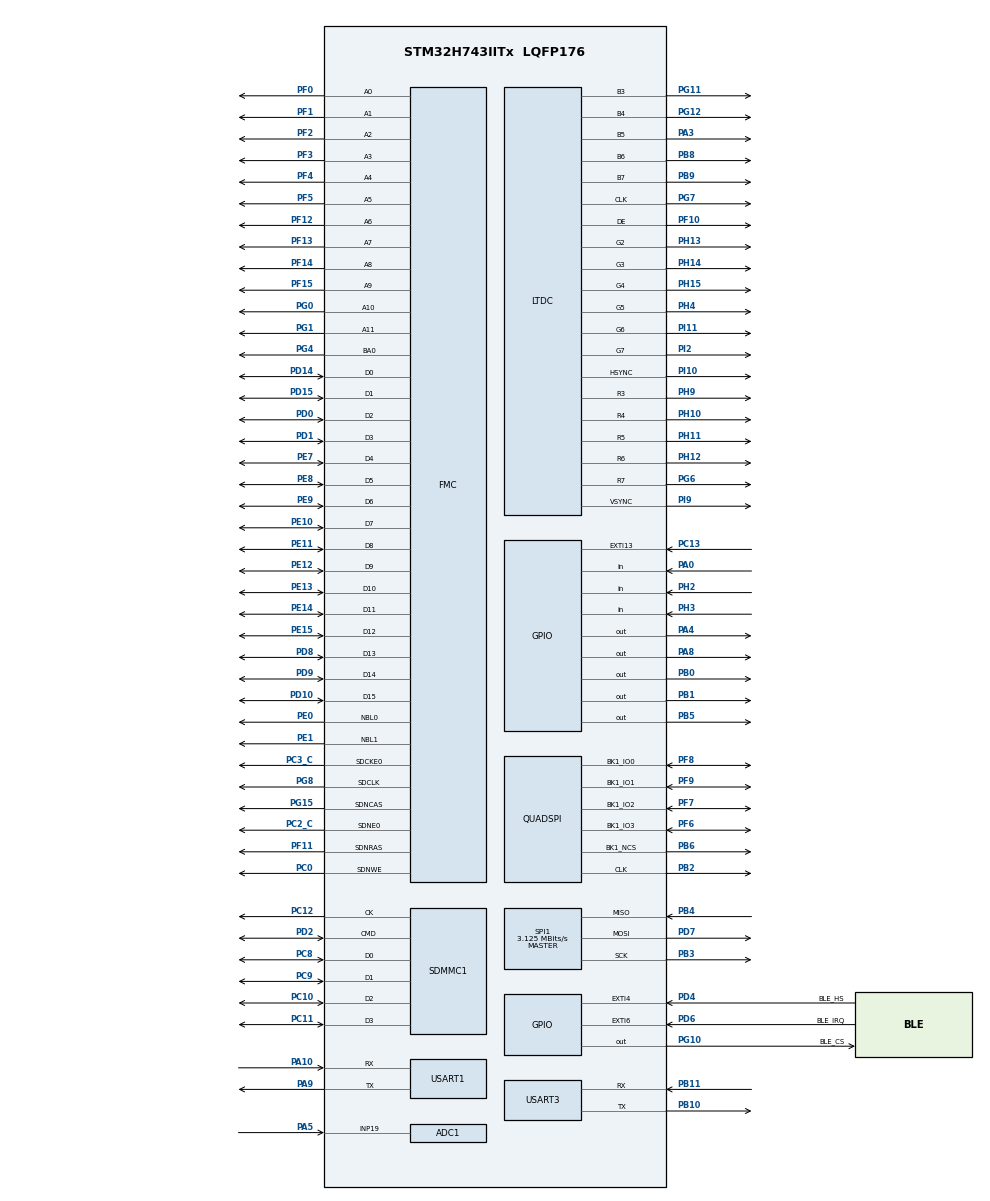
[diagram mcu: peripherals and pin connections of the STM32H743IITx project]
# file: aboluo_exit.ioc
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ADC1.Channel-0\#ChannelRegularConversion=ADC_CHANNEL_19
ADC1.NbrOfConversionFlag=1
ADC1.OffsetNumber-0\#ChannelRegularConversion=ADC_OFFSET_NONE
ADC1.OffsetSignedSaturation-0\#ChannelRegularConversion=DISABLE
ADC1.Rank-0\#ChannelRegularConversion=1
ADC1.SamplingTime-0\#ChannelRegularConversion=ADC_SAMPLETIME_1CYCLE_5
ADC1.master=1
CORTEX_M7.AccessPermission_S-Cortex_Memory_Protection_Unit_Region1_Settings_S=MPU_REGION_FULL_ACCESS
CORTEX_M7.AccessPermission_S-Cortex_Memory_Protection_Unit_Region2_Settings_S=MPU_REGION_FULL_ACCESS
CORTEX_M7.AccessPermission_S-Cortex_Memory_Protection_Unit_Region3_Settings_S=MPU_REGION_FULL_ACCESS
CORTEX_M7.AccessPermission_S-Cortex_Memory_Protection_Unit_Region4_Settings_S=MPU_REGION_FULL_ACCESS
CORTEX_M7.AccessPermission_S-Cortex_Memory_Protection_Unit_Region6_Settings_S=MPU_REGION_FULL_ACCESS
CORTEX_M7.AccessPermission_S-Cortex_Memory_Protection_Unit_Region7_Settings_S=MPU_REGION_FULL_ACCESS
CORTEX_M7.BaseAddress_S-Cortex_Memory_Protection_Unit_Region1_Settings_S=0x20000000
CORTEX_M7.BaseAddress_S-Cortex_Memory_Protection_Unit_Region2_Settings_S=0x24000000
CORTEX_M7.BaseAddress_S-Cortex_Memory_Protection_Unit_Region3_Settings_S=0x30000000
CORTEX_M7.BaseAddress_S-Cortex_Memory_Protection_Unit_Region4_Settings_S=0x38000000
CORTEX_M7.BaseAddress_S-Cortex_Memory_Protection_Unit_Region5_Settings_S=0x60000000
CORTEX_M7.BaseAddress_S-Cortex_Memory_Protection_Unit_Region6_Settings_S=0xC0000000
CORTEX_M7.BaseAddress_S-Cortex_Memory_Protection_Unit_Region7_Settings_S=0x80000000
CORTEX_M7.CPU_DCache=Enabled
CORTEX_M7.CPU_ICache=Enabled
CORTEX_M7.DisableExec_S-Cortex_Memory_Protection_Unit_Region7_Settings_S=MPU_INSTRUCTION_ACCESS_DISABLE
CORTEX_M7.Enable_S-Cortex_Memory_Protection_Unit_Region1_Settings_S=MPU_REGION_ENABLE
CORTEX_M7.Enable_S-Cortex_Memory_Protection_Unit_Region2_Settings_S=MPU_REGION_ENABLE
CORTEX_M7.Enable_S-Cortex_Memory_Protection_Unit_Region3_Settings_S=MPU_REGION_ENABLE
CORTEX_M7.Enable_S-Cortex_Memory_Protection_Unit_Region4_Settings_S=MPU_REGION_ENABLE
CORTEX_M7.Enable_S-Cortex_Memory_Protection_Unit_Region5_Settings_S=MPU_REGION_ENABLE
CORTEX_M7.Enable_S-Cortex_Memory_Protection_Unit_Region6_Settings_S=MPU_REGION_ENABLE
CORTEX_M7.Enable_S-Cortex_Memory_Protection_Unit_Region7_Settings_S=MPU_REGION_ENABLE
CORTEX_M7.IsBufferable_S-Cortex_Memory_Protection_Unit_Region1_Settings_S=MPU_ACCESS_BUFFERABLE
CORTEX_M7.IsBufferable_S-Cortex_Memory_Protection_Unit_Region2_Settings_S=MPU_ACCESS_BUFFERABLE
CORTEX_M7.IsBufferable_S-Cortex_Memory_Protection_Unit_Region3_Settings_S=MPU_ACCESS_BUFFERABLE
CORTEX_M7.IsBufferable_S-Cortex_Memory_Protection_Unit_Region4_Settings_S=MPU_ACCESS_BUFFERABLE
CORTEX_M7.IsBufferable_S-Cortex_Memory_Protection_Unit_Region6_Settings_S=MPU_ACCESS_NOT_BUFFERABLE
CORTEX_M7.IsCacheable_S-Cortex_Memory_Protection_Unit_Region1_Settings_S=MPU_ACCESS_CACHEABLE
CORTEX_M7.IsCacheable_S-Cortex_Memory_Protection_Unit_Region2_Settings_S=MPU_ACCESS_CACHEABLE
CORTEX_M7.IsCacheable_S-Cortex_Memory_Protection_Unit_Region3_Settings_S=MPU_ACCESS_CACHEABLE
CORTEX_M7.IsCacheable_S-Cortex_Memory_Protection_Unit_Region4_Settings_S=MPU_ACCESS_CACHEABLE
CORTEX_M7.IsCacheable_S-Cortex_Memory_Protection_Unit_Region6_Settings_S=MPU_ACCESS_CACHEABLE
CORTEX_M7.Size_S-Cortex_Memory_Protection_Unit_Region1_Settings_S=MPU_REGION_SIZE_128KB
CORTEX_M7.Size_S-Cortex_Memory_Protection_Unit_Region2_Settings_S=MPU_REGION_SIZE_512KB
CORTEX_M7.Size_S-Cortex_Memory_Protection_Unit_Region3_Settings_S=MPU_REGION_SIZE_512KB
CORTEX_M7.Size_S-Cortex_Memory_Protection_Unit_Region4_Settings_S=MPU_REGION_SIZE_64KB
CORTEX_M7.Size_S-Cortex_Memory_Protection_Unit_Region5_Settings_S=MPU_REGION_SIZE_64MB
CORTEX_M7.Size_S-Cortex_Memory_Protection_Unit_Region6_Settings_S=MPU_REGION_SIZE_32MB
CORTEX_M7.Size_S-Cortex_Memory_Protection_Unit_Region7_Settings_S=MPU_REGION_SIZE_256MB
CORTEX_M7.default_mode_Activation=1
DMA2D.ColorMode=DMA2D_OUTPUT_RGB565
Dma.Request0=USART1_RX
Dma.Request1=USART3_RX
Dma.Request2=SPI1_RX
Dma.Request3=SPI1_TX
Dma.SPI1_RX.2.Direction=DMA_PERIPH_TO_MEMORY
Dma.SPI1_RX.2.EventEnable=DISABLE
Dma.SPI1_RX.2.FIFOMode=DMA_FIFOMODE_DISABLE
Dma.SPI1_RX.2.Instance=DMA1_Stream2
Dma.SPI1_RX.2.MemDataAlignment=DMA_MDATAALIGN_BYTE
Dma.SPI1_RX.2.MemInc=DMA_MINC_ENABLE
Dma.SPI1_RX.2.Mode=DMA_NORMAL
Dma.SPI1_RX.2.PeriphDataAlignment=DMA_PDATAALIGN_BYTE
Dma.SPI1_RX.2.PeriphInc=DMA_PINC_DISABLE
Dma.SPI1_RX.2.Polarity=HAL_DMAMUX_REQ_GEN_RISING
Dma.SPI1_RX.2.Priority=DMA_PRIORITY_HIGH
Dma.SPI1_RX.2.RequestNumber=1
Dma.SPI1_RX.2.SignalID=NONE
Dma.SPI1_RX.2.SyncEnable=DISABLE
Dma.SPI1_RX.2.SyncPolarity=HAL_DMAMUX_SYNC_NO_EVENT
Dma.SPI1_RX.2.SyncRequestNumber=1
Dma.SPI1_RX.2.SyncSignalID=NONE
Dma.SPI1_TX.3.Direction=DMA_MEMORY_TO_PERIPH
Dma.SPI1_TX.3.EventEnable=DISABLE
Dma.SPI1_TX.3.FIFOMode=DMA_FIFOMODE_DISABLE
Dma.SPI1_TX.3.Instance=DMA1_Stream3
Dma.SPI1_TX.3.MemDataAlignment=DMA_MDATAALIGN_BYTE
Dma.SPI1_TX.3.MemInc=DMA_MINC_ENABLE
Dma.SPI1_TX.3.Mode=DMA_NORMAL
Dma.SPI1_TX.3.PeriphDataAlignment=DMA_PDATAALIGN_BYTE
Dma.SPI1_TX.3.PeriphInc=DMA_PINC_DISABLE
Dma.SPI1_TX.3.Polarity=HAL_DMAMUX_REQ_GEN_RISING
Dma.SPI1_TX.3.Priority=DMA_PRIORITY_LOW
Dma.SPI1_TX.3.RequestNumber=1
Dma.SPI1_TX.3.SignalID=NONE
Dma.SPI1_TX.3.SyncEnable=DISABLE
Dma.SPI1_TX.3.SyncPolarity=HAL_DMAMUX_SYNC_NO_EVENT
Dma.SPI1_TX.3.SyncRequestNumber=1
Dma.SPI1_TX.3.SyncSignalID=NONE
Dma.USART1_RX.0.Direction=DMA_PERIPH_TO_MEMORY
Dma.USART1_RX.0.EventEnable=DISABLE
Dma.USART1_RX.0.FIFOMode=DMA_FIFOMODE_DISABLE
Dma.USART1_RX.0.Instance=DMA1_Stream0
Dma.USART1_RX.0.MemDataAlignment=DMA_MDATAALIGN_BYTE
Dma.USART1_RX.0.MemInc=DMA_MINC_ENABLE
Dma.USART1_RX.0.Mode=DMA_CIRCULAR
Dma.USART1_RX.0.PeriphDataAlignment=DMA_PDATAALIGN_BYTE
Dma.USART1_RX.0.PeriphInc=DMA_PINC_DISABLE
Dma.USART1_RX.0.Polarity=HAL_DMAMUX_REQ_GEN_RISING
Dma.USART1_RX.0.Priority=DMA_PRIORITY_LOW
Dma.USART1_RX.0.RequestNumber=1
Dma.USART1_RX.0.SignalID=NONE
Dma.USART1_RX.0.SyncEnable=DISABLE
Dma.USART1_RX.0.SyncPolarity=HAL_DMAMUX_SYNC_NO_EVENT
Dma.USART1_RX.0.SyncRequestNumber=1
Dma.USART1_RX.0.SyncSignalID=NONE
Dma.USART3_RX.1.Direction=DMA_PERIPH_TO_MEMORY
Dma.USART3_RX.1.EventEnable=DISABLE
Dma.USART3_RX.1.FIFOMode=DMA_FIFOMODE_DISABLE
Dma.USART3_RX.1.Instance=DMA1_Stream1
Dma.USART3_RX.1.MemDataAlignment=DMA_MDATAALIGN_BYTE
Dma.USART3_RX.1.MemInc=DMA_MINC_ENABLE
Dma.USART3_RX.1.Mode=DMA_CIRCULAR
Dma.USART3_RX.1.PeriphDataAlignment=DMA_PDATAALIGN_BYTE
Dma.USART3_RX.1.PeriphInc=DMA_PINC_DISABLE
Dma.USART3_RX.1.Polarity=HAL_DMAMUX_REQ_GEN_RISING
Dma.USART3_RX.1.Priority=DMA_PRIORITY_LOW
Dma.USART3_RX.1.RequestNumber=1
Dma.USART3_RX.1.SignalID=NONE
Dma.USART3_RX.1.SyncEnable=DISABLE
Dma.USART3_RX.1.SyncPolarity=HAL_DMAMUX_SYNC_NO_EVENT
Dma.USART3_RX.1.SyncRequestNumber=1
Dma.USART3_RX.1.SyncSignalID=NONE
Mcu.Family=STM32H7
Mcu.Name=STM32H743IITx
Mcu.Package=LQFP176
NVIC.DMA1_Stream0_IRQn=true\:0\:0\:false\:false\:true\:true\:false\:true\:true
NVIC.DMA1_Stream1_IRQn=true\:0\:0\:false\:false\:true\:true\:false\:true\:true
NVIC.DMA1_Stream2_IRQn=true\:0\:0\:false\:false\:true\:true\:false\:true\:true
NVIC.DMA1_Stream3_IRQn=true\:0\:0\:false\:false\:true\:true\:false\:true\:true
NVIC.DMA2D_IRQn=true\:0\:0\:false\:false\:true\:false\:true\:true\:true
NVIC.EXTI15_10_IRQn=true\:0\:0\:false\:false\:true\:false\:true\:true\:true
NVIC.EXTI4_IRQn=true\:0\:0\:false\:false\:true\:false\:true\:true\:true
NVIC.EXTI9_5_IRQn=true\:0\:0\:false\:false\:true\:false\:true\:true\:true
NVIC.PriorityGroup=NVIC_PRIORITYGROUP_4
NVIC.RCC_IRQn=true\:0\:0\:false\:false\:true\:false\:true\:false\:true
NVIC.SPI1_IRQn=true\:0\:0\:false\:false\:true\:false\:true\:true\:true
NVIC.TIM6_DAC_IRQn=true\:0\:0\:true\:false\:true\:false\:false\:true\:true
NVIC.TimeBase=TIM6_DAC_IRQn
NVIC.TimeBaseIP=TIM6
NVIC.USART1_IRQn=true\:0\:0\:false\:false\:true\:false\:true\:true\:true
NVIC.USART3_IRQn=true\:0\:0\:false\:false\:true\:false\:true\:true\:true
PA0.GPIO_PuPd=GPIO_PULLDOWN
PA0.Signal=GPIO_Input
PA1.Signal=ETH_REF_CLK
PA10.Mode=Asynchronous
PA10.Signal=USART1_RX
PA11.Signal=FDCAN1_RX
PA12.Signal=FDCAN1_TX
PA13\ (JTMS/SWDIO).Mode=Serial_Wire
PA13\ (JTMS/SWDIO).Signal=DEBUG_JTMS-SWDIO
PA14\ (JTCK/SWCLK).Mode=Serial_Wire
PA14\ (JTCK/SWCLK).Signal=DEBUG_JTCK-SWCLK
PA15\ (JTDI).Signal=DEBUG_JTDI
PA2.Signal=ETH_MDIO
PA3.Mode=RGB565
PA3.Signal=LTDC_B5
PA4.Signal=GPIO_Output
PA5.Signal=ADCx_INP19
PA6.Signal=DCMI_PIXCLK
PA7.Signal=ETH_CRS_DV
PA8.Signal=GPIO_Output
PA9.Mode=Asynchronous
PA9.Signal=USART1_TX
PB0.Signal=GPIO_Output
PB1.Signal=GPIO_Output
PB10.Mode=Asynchronous
PB10.Signal=USART3_TX
PB11.Mode=Asynchronous
PB11.Signal=USART3_RX
PB2.Mode=Single Bank 1
PB2.Signal=QUADSPI_CLK
PB3\ (JTDO/TRACESWO).Mode=Full_Duplex_Master
PB3\ (JTDO/TRACESWO).Signal=SPI1_SCK
PB4\ (NJTRST).Mode=Full_Duplex_Master
PB4\ (NJTRST).Signal=SPI1_MISO
PB5.Signal=GPIO_Output
PB6.Mode=Single Bank 1
PB6.Signal=QUADSPI_BK1_NCS
PB8.Mode=RGB565
PB8.Signal=LTDC_B6
PB9.Mode=RGB565
PB9.Signal=LTDC_B7
PC0.Signal=FMC_SDNWE
PC1.Signal=ETH_MDC
PC10.Mode=SD_4_bits_Wide_bus
PC10.Signal=SDMMC1_D2
PC11.Mode=SD_4_bits_Wide_bus
PC11.Signal=SDMMC1_D3
PC12.Mode=SD_4_bits_Wide_bus
PC12.Signal=SDMMC1_CK
PC13.GPIO_ModeDefaultEXTI=GPIO_MODE_IT_FALLING
PC13.GPIO_PuPd=GPIO_PULLUP
PC13.Signal=GPXTI13
PC14-OSC32_IN\ (OSC32_IN).Mode=LSE-External-Oscillator
PC14-OSC32_IN\ (OSC32_IN).Signal=RCC_OSC32_IN
PC15-OSC32_OUT\ (OSC32_OUT).Mode=LSE-External-Oscillator
PC15-OSC32_OUT\ (OSC32_OUT).Signal=RCC_OSC32_OUT
PC2_C.Mode=SdramChipSelect1_1
PC2_C.Signal=FMC_SDNE0
PC3_C.Mode=SdramChipSelect1_1
PC3_C.Signal=FMC_SDCKE0
PC4.Signal=ETH_RXD0
PC5.Signal=ETH_RXD1
PC8.Mode=SD_4_bits_Wide_bus
PC8.Signal=SDMMC1_D0
PC9.Mode=SD_4_bits_Wide_bus
PC9.Signal=SDMMC1_D1
PD0.Signal=FMC_D2_DA2
PD1.Signal=FMC_D3_DA3
PD10.Signal=FMC_D15_DA15
PD14.Signal=FMC_D0_DA0
PD15.Signal=FMC_D1_DA1
PD2.Mode=SD_4_bits_Wide_bus
PD2.Signal=SDMMC1_CMD
PD4.GPIO_Label=BLE_HS
PD4.GPIO_ModeDefaultEXTI=GPIO_MODE_IT_RISING
PD4.GPIO_PuPd=GPIO_PULLDOWN
PD4.Signal=GPXTI4
PD6.GPIO_Label=BLE_IRQ
PD6.GPIO_PuPd=GPIO_PULLDOWN
PD6.Signal=GPXTI6
PD7.Mode=Full_Duplex_Master
PD7.Signal=SPI1_MOSI
PD8.Signal=FMC_D13_DA13
PD9.Signal=FMC_D14_DA14
PE0.Signal=FMC_NBL0
PE1.Signal=FMC_NBL1
PE10.Signal=FMC_D7_DA7
PE11.Signal=FMC_D8_DA8
PE12.Signal=FMC_D9_DA9
PE13.Signal=FMC_D10_DA10
PE14.Signal=FMC_D11_DA11
PE15.Signal=FMC_D12_DA12
PE7.Signal=FMC_D4_DA4
PE8.Signal=FMC_D5_DA5
PE9.Signal=FMC_D6_DA6
PF0.Signal=FMC_A0
PF1.Signal=FMC_A1
PF10.Mode=RGB565
PF10.Signal=LTDC_DE
PF11.Signal=FMC_SDNRAS
PF12.Signal=FMC_A6
PF13.Signal=FMC_A7
PF14.Signal=FMC_A8
PF15.Signal=FMC_A9
PF2.Signal=FMC_A2
PF3.Signal=FMC_A3
PF4.Signal=FMC_A4
PF5.Signal=FMC_A5
PF6.Mode=Single Bank 1
PF6.Signal=QUADSPI_BK1_IO3
PF7.Mode=Single Bank 1
PF7.Signal=QUADSPI_BK1_IO2
PF8.Mode=Single Bank 1
PF8.Signal=QUADSPI_BK1_IO0
PF9.Mode=Single Bank 1
PF9.Signal=QUADSPI_BK1_IO1
PG0.Signal=FMC_A10
PG1.Signal=FMC_A11
PG10.GPIO_Label=BLE_CS
PG10.Signal=GPIO_Output
PG11.Mode=RGB565
PG11.Signal=LTDC_B3
PG12.Mode=RGB565
PG12.Signal=LTDC_B4
PG15.Signal=FMC_SDNCAS
PG4.Signal=FMC_A14_BA0
PG6.Mode=RGB565
PG6.Signal=LTDC_R7
PG7.Mode=RGB565
PG7.Signal=LTDC_CLK
PG8.Signal=FMC_SDCLK
PH0-OSC_IN\ (PH0).Mode=HSE-External-Oscillator
PH0-OSC_IN\ (PH0).Signal=RCC_OSC_IN
PH1-OSC_OUT\ (PH1).Mode=HSE-External-Oscillator
PH1-OSC_OUT\ (PH1).Signal=RCC_OSC_OUT
PH10.Mode=RGB565
PH10.Signal=LTDC_R4
PH11.Mode=RGB565
PH11.Signal=LTDC_R5
PH12.Mode=RGB565
PH12.Signal=LTDC_R6
PH13.Mode=RGB565
PH13.Signal=LTDC_G2
PH14.Mode=RGB565
PH14.Signal=LTDC_G3
PH15.Mode=RGB565
PH15.Signal=LTDC_G4
PH2.Signal=GPIO_Input
PH3.Signal=GPIO_Input
PH4.Mode=RGB565
PH4.Signal=LTDC_G5
PH9.Mode=RGB565
PH9.Signal=LTDC_R3
PI10.Mode=RGB565
PI10.Signal=LTDC_HSYNC
PI11.Mode=RGB565
PI11.Signal=LTDC_G6
PI2.Mode=RGB565
PI2.Signal=LTDC_G7
PI9.Mode=RGB565
PI9.Signal=LTDC_VSYNC
ProjectManager.HeapSize=0xC000
ProjectManager.StackSize=0x4000
ProjectManager.TargetToolchain=CMake
RCC.ADCFreq_Value=93750000
RCC.APB1Freq_Value=50000000
RCC.APB2Freq_Value=50000000
RCC.APB3Freq_Value=50000000
RCC.APB4Freq_Value=50000000
RCC.CortexFreq_Value=400000000
RCC.D1PPRE=RCC_APB3_DIV4
RCC.D2PPRE1=RCC_APB1_DIV4
RCC.D2PPRE2=RCC_APB2_DIV4
RCC.D3PPRE=RCC_APB4_DIV4
RCC.DIVM1=5
RCC.DIVM2=4
RCC.DIVM3=1
RCC.DIVN1=160
RCC.DIVN2=30
RCC.DIVN3=6
RCC.DIVQ1=4
RCC.DIVR1=4
RCC.DIVR3=6
RCC.HCLKFreq_Value=200000000
RCC.HPRE=RCC_HCLK_DIV2
RCC.PLLSourceVirtual=RCC_PLLSOURCE_HSE
RCC.RTCClockSelection=RCC_RTCCLKSOURCE_LSE
RCC.SYSCLKFreq_VALUE=400000000
RCC.SYSCLKSource=RCC_SYSCLKSOURCE_PLLCLK
RCC.USBFreq_Value=200000000
RTC.Date=30
RTC.Format=RTC_FORMAT_BIN
RTC.Month=RTC_MONTH_DECEMBER
RTC.WeekDay=RTC_WEEKDAY_TUESDAY
RTC.Year=2025
SH.ADCx_INP19.0=ADC1_INP19,IN19-Single-Ended
SH.FMC_A0.0=FMC_A0,12b-sda1
SH.FMC_A1.0=FMC_A1,12b-sda1
SH.FMC_A10.0=FMC_A10,12b-sda1
SH.FMC_A11.0=FMC_A11,12b-sda1
SH.FMC_A14_BA0.0=FMC_BA0,TwoSdramBanks1
SH.FMC_A2.0=FMC_A2,12b-sda1
SH.FMC_A3.0=FMC_A3,12b-sda1
SH.FMC_A4.0=FMC_A4,12b-sda1
SH.FMC_A5.0=FMC_A5,12b-sda1
SH.FMC_A6.0=FMC_A6,12b-sda1
SH.FMC_A7.0=FMC_A7,12b-sda1
SH.FMC_A8.0=FMC_A8,12b-sda1
SH.FMC_A9.0=FMC_A9,12b-sda1
SH.FMC_D0_DA0.0=FMC_D0,sd-16b-d1
SH.FMC_D10_DA10.0=FMC_D10,sd-16b-d1
SH.FMC_D11_DA11.0=FMC_D11,sd-16b-d1
SH.FMC_D12_DA12.0=FMC_D12,sd-16b-d1
SH.FMC_D13_DA13.0=FMC_D13,sd-16b-d1
SH.FMC_D14_DA14.0=FMC_D14,sd-16b-d1
SH.FMC_D15_DA15.0=FMC_D15,sd-16b-d1
SH.FMC_D1_DA1.0=FMC_D1,sd-16b-d1
SH.FMC_D2_DA2.0=FMC_D2,sd-16b-d1
SH.FMC_D3_DA3.0=FMC_D3,sd-16b-d1
SH.FMC_D4_DA4.0=FMC_D4,sd-16b-d1
SH.FMC_D5_DA5.0=FMC_D5,sd-16b-d1
SH.FMC_D6_DA6.0=FMC_D6,sd-16b-d1
SH.FMC_D7_DA7.0=FMC_D7,sd-16b-d1
SH.FMC_D8_DA8.0=FMC_D8,sd-16b-d1
SH.FMC_D9_DA9.0=FMC_D9,sd-16b-d1
SH.FMC_NBL0.0=FMC_NBL0,Sd2ByteEnable1
SH.FMC_NBL1.0=FMC_NBL1,Sd2ByteEnable1
SH.FMC_SDCLK.0=FMC_SDCLK,12b-sda1
SH.FMC_SDNCAS.0=FMC_SDNCAS,12b-sda1
SH.FMC_SDNRAS.0=FMC_SDNRAS,12b-sda1
SH.FMC_SDNWE.0=FMC_SDNWE,12b-sda1
SPI1.BaudRatePrescaler=SPI_BAUDRATEPRESCALER_64
SPI1.CLKPhase=SPI_PHASE_2EDGE
SPI1.CLKPolarity=SPI_POLARITY_HIGH
SPI1.CalculateBaudRate=3.125 MBits/s
SPI1.DataSize=SPI_DATASIZE_8BIT
SPI1.Direction=SPI_DIRECTION_2LINES
SPI1.Mode=SPI_MODE_MASTER
SPI1.NSSPMode=SPI_NSS_PULSE_DISABLE
SPI1.VirtualType=VM_MASTER
STMicroelectronics.X-CUBE-AZRTOS-H7.3.3.0.TX_APP_CREATION=1
STMicroelectronics.X-CUBE-AZRTOS-H7.3.3.0.TX_APP_GENERATE_INIT_CODE=true
STMicroelectronics.X-CUBE-AZRTOS-H7.3.3.0.TX_APP_MEM_POOL_SIZE=32768
STMicroelectronics.X-CUBE-AZRTOS-H7.3.3.0.TX_APP_STACK_SIZE=1024
STMicroelectronics.X-CUBE-AZRTOS-H7.3.3.0.TX_INLINE_THREAD_RESUME_SUSPEND=1
STMicroelectronics.X-CUBE-AZRTOS-H7.3.3.0.TX_MINIMUM_STACK=1024
STMicroelectronics.X-CUBE-AZRTOS-H7.3.3.0.TX_REACTIVATE_INLINE=1
STMicroelectronics.X-CUBE-AZRTOS-H7.3.3.0.TX_TIMER_TICKS_PER_SECOND=1000
STMicroelectronics.X-CUBE-AZRTOS-H7.3.3.0.ThreadXCcRTOSJjThreadXJjCore=true
STMicroelectronics.X-CUBE-AZRTOS-H7.3.3.0.ThreadXCcRTOSJjThreadXJjLowOoPowerOosupport=true
STMicroelectronics.X-CUBE-AZRTOS-H7.3.3.0.ThreadXCcRTOSJjThreadXJjPerformanceInfo=true
STMicroelectronics.X-CUBE-AZRTOS-H7.3.3.0.ThreadXCcRTOSJjThreadXJjTraceXOosupport=true
STMicroelectronics.X-CUBE-AZRTOS-H7.3.3.0_IsAnAzureRtosMw=true
USART1.VirtualMode-Asynchronous=VM_ASYNC
USART3.VirtualMode-Asynchronous=VM_ASYNC
VP_CRC_VS_CRC.Mode=CRC_Activate
VP_DMA2D_VS_DMA2D.Mode=DMA2D_Activate
VP_MEMORYMAP_VS_MEMORYMAP.Mode=CurAppReg
VP_RNG_VS_RNG.Mode=RNG_Activate
VP_RTC_VS_RTC_Activate.Mode=RTC_Enabled
VP_RTC_VS_RTC_Calendar.Mode=RTC_Calendar
VP_STMicroelectronics.X-CUBE-AZRTOS-H7_VS_RTOSJjThreadX_6.4.0_3.3.0.Mode=RTOSJjThreadX
VP_SYS_VS_tim6.Mode=TIM6
board=custom

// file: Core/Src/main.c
/* USER CODE BEGIN Header */
/* USER CODE END Header */
#include "app_threadx.h"
#include "main.h"
#include "adc.h"
#include "crc.h"
#include "dma.h"
#include "dma2d.h"
#include "ltdc.h"
#include "memorymap.h"
#include "quadspi.h"
#include "rng.h"
#include "rtc.h"
#include "sdmmc.h"
#include "spi.h"
#include "usart.h"
#include "gpio.h"
#include "fmc.h"

/* USER CODE BEGIN Includes */
#include "app_log.h"
#include "atk_rgblcd.h"
#include "ble_client.h"
#include "crypto_utils.h"
#include "dwt_clk.h"
#include "sdram.h"
#include "lv_port_disp.h"
#include "src/lv_init.h"
#include "lvgl.h"
#include "stm32h7xx_hal_dma2d.h"
#include "TimeUtils.h"
#include "ui.h"
/* USER CODE END Includes */

void SystemClock_Config(void);
static void MPU_Config(void);

/* USER CODE BEGIN 0 */
void my_stack_error_handler(TX_THREAD *thread_ptr)
{
  // 如果跑到这里，说明真的栈溢出了！
  LOG_PRINT("ERROR: Stack Overflow detected in thread: %s\n", thread_ptr->tx_thread_name);
  while(1); // 卡在这里方便调试
}
/* USER CODE END 0 */

int main(void)
{

  /* MPU Configuration--------------------------------------------------------*/
  MPU_Config();

  /* Enable the CPU Cache */

  /* Enable I-Cache---------------------------------------------------------*/
  SCB_EnableICache();

  /* Enable D-Cache---------------------------------------------------------*/
  SCB_EnableDCache();

  /* MCU Configuration--------------------------------------------------------*/

  /* Reset of all peripherals, Initializes the Flash interface and the Systick. */
  HAL_Init();

  /* Configure the system clock */
  SystemClock_Config();

  /* Initialize all configured peripherals */
  MX_GPIO_Init();
  MX_DMA_Init();
  MX_ADC1_Init();
  MX_FMC_Init();
  MX_QUADSPI_Init();
  MX_SDMMC1_SD_Init();
  MX_USART1_UART_Init();
  MX_USART3_UART_Init();
  MX_CRC_Init();
  MX_DMA2D_Init();
  MX_LTDC_Init();
  MX_RNG_Init();
  MX_SPI1_Init();
  MX_RTC_Init();
  /* USER CODE BEGIN 2 */
  DWT_Delay_Init();
  sdram_init();
  atk_rgblcd_init();
  atk_rgblcd_display_on();
  atk_rgblcd_clear(ATK_RGBLCD_WHITE);
  lv_init();
  lv_port_disp_init();
  lv_port_touch_init();
  // create_touch_test_ui();
  // lv_example_test();
  ui_init();
  tx_thread_stack_error_notify(my_stack_error_handler);
  HAL_GPIO_WritePin(GPIOA, GPIO_PIN_4, GPIO_PIN_SET);
  crypto_init();
  /* USER CODE END 2 */

  MX_ThreadX_Init();

  /* We should never get here as control is now taken by the scheduler */

  /* Infinite loop */
  /* USER CODE BEGIN WHILE */
  // while (1)
  // {
  //   lv_timer_handler(); // 处理UI绘制任务
  //   HAL_Delay(5);       // 必须有短暂延时，给系统喘息
  // }
    /* USER CODE END WHILE */

}

void SystemClock_Config(void)
{
  RCC_OscInitTypeDef RCC_OscInitStruct = {0};
  RCC_ClkInitTypeDef RCC_ClkInitStruct = {0};

  /** Supply configuration update enable
  */
  HAL_PWREx_ConfigSupply(PWR_LDO_SUPPLY);

  /** Configure the main internal regulator output voltage
  */
  __HAL_PWR_VOLTAGESCALING_CONFIG(PWR_REGULATOR_VOLTAGE_SCALE1);

  while(!__HAL_PWR_GET_FLAG(PWR_FLAG_VOSRDY)) {}

  /** Configure LSE Drive Capability
  */
  HAL_PWR_EnableBkUpAccess();
  __HAL_RCC_LSEDRIVE_CONFIG(RCC_LSEDRIVE_LOW);

  /** Initializes the RCC Oscillators according to the specified parameters
  * in the RCC_OscInitTypeDef structure.
  */
  RCC_OscInitStruct.OscillatorType = RCC_OSCILLATORTYPE_HSI48|RCC_OSCILLATORTYPE_HSE
                              |RCC_OSCILLATORTYPE_LSE;
  RCC_OscInitStruct.HSEState = RCC_HSE_ON;
  RCC_OscInitStruct.LSEState = RCC_LSE_ON;
  RCC_OscInitStruct.HSI48State = RCC_HSI48_ON;
  RCC_OscInitStruct.PLL.PLLState = RCC_PLL_ON;
  RCC_OscInitStruct.PLL.PLLSource = RCC_PLLSOURCE_HSE;
  RCC_OscInitStruct.PLL.PLLM = 5;
  RCC_OscInitStruct.PLL.PLLN = 160;
  RCC_OscInitStruct.PLL.PLLP = 2;
  RCC_OscInitStruct.PLL.PLLQ = 4;
  RCC_OscInitStruct.PLL.PLLR = 4;
  RCC_OscInitStruct.PLL.PLLRGE = RCC_PLL1VCIRANGE_2;
  RCC_OscInitStruct.PLL.PLLVCOSEL = RCC_PLL1VCOWIDE;
  RCC_OscInitStruct.PLL.PLLFRACN = 0;
  if (HAL_RCC_OscConfig(&RCC_OscInitStruct) != HAL_OK)
  {
    Error_Handler();
  }

  /** Initializes the CPU, AHB and APB buses clocks
  */
  RCC_ClkInitStruct.ClockType = RCC_CLOCKTYPE_HCLK|RCC_CLOCKTYPE_SYSCLK
                              |RCC_CLOCKTYPE_PCLK1|RCC_CLOCKTYPE_PCLK2
                              |RCC_CLOCKTYPE_D3PCLK1|RCC_CLOCKTYPE_D1PCLK1;
  RCC_ClkInitStruct.SYSCLKSource = RCC_SYSCLKSOURCE_PLLCLK;
  RCC_ClkInitStruct.SYSCLKDivider = RCC_SYSCLK_DIV1;
  RCC_ClkInitStruct.AHBCLKDivider = RCC_HCLK_DIV2;
  RCC_ClkInitStruct.APB3CLKDivider = RCC_APB3_DIV4;
  RCC_ClkInitStruct.APB1CLKDivider = RCC_APB1_DIV4;
  RCC_ClkInitStruct.APB2CLKDivider = RCC_APB2_DIV4;
  RCC_ClkInitStruct.APB4CLKDivider = RCC_APB4_DIV4;

  if (HAL_RCC_ClockConfig(&RCC_ClkInitStruct, FLASH_LATENCY_2) != HAL_OK)
  {
    Error_Handler();
  }
}

 /* MPU Configuration */

void MPU_Config(void)
{
  MPU_Region_InitTypeDef MPU_InitStruct = {0};

  /* Disables the MPU */
  HAL_MPU_Disable();

  /** Initializes and configures the Region and the memory to be protected
  */
  MPU_InitStruct.Enable = MPU_REGION_ENABLE;
  MPU_InitStruct.Number = MPU_REGION_NUMBER0;
  MPU_InitStruct.BaseAddress = 0x0;
  MPU_InitStruct.Size = MPU_REGION_SIZE_4GB;
  MPU_InitStruct.SubRegionDisable = 0x87;
  MPU_InitStruct.TypeExtField = MPU_TEX_LEVEL0;
  MPU_InitStruct.AccessPermission = MPU_REGION_NO_ACCESS;
  MPU_InitStruct.DisableExec = MPU_INSTRUCTION_ACCESS_DISABLE;
  MPU_InitStruct.IsShareable = MPU_ACCESS_SHAREABLE;
  MPU_InitStruct.IsCacheable = MPU_ACCESS_NOT_CACHEABLE;
  MPU_InitStruct.IsBufferable = MPU_ACCESS_NOT_BUFFERABLE;

  HAL_MPU_ConfigRegion(&MPU_InitStruct);

  /** Initializes and configures the Region and the memory to be protected
  */
  MPU_InitStruct.Number = MPU_REGION_NUMBER1;
  MPU_InitStruct.BaseAddress = 0x20000000;
  MPU_InitStruct.Size = MPU_REGION_SIZE_128KB;
  MPU_InitStruct.SubRegionDisable = 0x0;
  MPU_InitStruct.AccessPermission = MPU_REGION_FULL_ACCESS;
  MPU_InitStruct.DisableExec = MPU_INSTRUCTION_ACCESS_ENABLE;
  MPU_InitStruct.IsShareable = MPU_ACCESS_NOT_SHAREABLE;
  MPU_InitStruct.IsCacheable = MPU_ACCESS_CACHEABLE;
  MPU_InitStruct.IsBufferable = MPU_ACCESS_BUFFERABLE;

  HAL_MPU_ConfigRegion(&MPU_InitStruct);

  /** Initializes and configures the Region and the memory to be protected
  */
  MPU_InitStruct.Number = MPU_REGION_NUMBER2;
  MPU_InitStruct.BaseAddress = 0x24000000;
  MPU_InitStruct.Size = MPU_REGION_SIZE_512KB;

  HAL_MPU_ConfigRegion(&MPU_InitStruct);

  /** Initializes and configures the Region and the memory to be protected
  */
  MPU_InitStruct.Number = MPU_REGION_NUMBER3;
  MPU_InitStruct.BaseAddress = 0x30000000;

  HAL_MPU_ConfigRegion(&MPU_InitStruct);

  /** Initializes and configures the Region and the memory to be protected
  */
  MPU_InitStruct.Number = MPU_REGION_NUMBER4;
  MPU_InitStruct.BaseAddress = 0x38000000;
  MPU_InitStruct.Size = MPU_REGION_SIZE_64KB;

  HAL_MPU_ConfigRegion(&MPU_InitStruct);

  /** Initializes and configures the Region and the memory to be protected
  */
  MPU_InitStruct.Number = MPU_REGION_NUMBER5;
  MPU_InitStruct.BaseAddress = 0x60000000;
  MPU_InitStruct.Size = MPU_REGION_SIZE_64MB;
  MPU_InitStruct.AccessPermission = MPU_REGION_NO_ACCESS;
  MPU_InitStruct.IsCacheable = MPU_ACCESS_NOT_CACHEABLE;
  MPU_InitStruct.IsBufferable = MPU_ACCESS_NOT_BUFFERABLE;

  HAL_MPU_ConfigRegion(&MPU_InitStruct);

  /** Initializes and configures the Region and the memory to be protected
  */
  MPU_InitStruct.Number = MPU_REGION_NUMBER6;
  MPU_InitStruct.BaseAddress = 0xC0000000;
  MPU_InitStruct.Size = MPU_REGION_SIZE_32MB;
  MPU_InitStruct.AccessPermission = MPU_REGION_FULL_ACCESS;
  MPU_InitStruct.IsCacheable = MPU_ACCESS_CACHEABLE;

  HAL_MPU_ConfigRegion(&MPU_InitStruct);

  /** Initializes and configures the Region and the memory to be protected
  */
  MPU_InitStruct.Number = MPU_REGION_NUMBER7;
  MPU_InitStruct.BaseAddress = 0x80000000;
  MPU_InitStruct.Size = MPU_REGION_SIZE_256MB;
  MPU_InitStruct.DisableExec = MPU_INSTRUCTION_ACCESS_DISABLE;
  MPU_InitStruct.IsCacheable = MPU_ACCESS_NOT_CACHEABLE;

  HAL_MPU_ConfigRegion(&MPU_InitStruct);
  /* Enables the MPU */
  HAL_MPU_Enable(MPU_PRIVILEGED_DEFAULT);

}

void HAL_TIM_PeriodElapsedCallback(TIM_HandleTypeDef *htim)
{
  if (htim->Instance == TIM6)
  {
    HAL_IncTick();
  }
  /* USER CODE BEGIN Callback 1 */
  if (htim->Instance == TIM6)
  {
    lv_tick_inc(1);
  }
  /* USER CODE END Callback 1 */
}

void Error_Handler(void)
{
  /* USER CODE BEGIN Error_Handler_Debug */
  LOG_PRINT("error\n");
  /* USER CODE END Error_Handler_Debug */
}
